# BlueNRG_LPF register map
File version: 1.0
CPU: CM0+ r0p0, little endian, no MPU, no FPU, 2 interrupt priority bits
Registers are 32-bit, read-write, reset 0x0 unless marked. A register's access mark holds for its fields unless they carry their own. Offsets are from the block's base; [hi:lo] are bit positions; {n}, {i} and the like mark numbered series.

## PWR
Base 0x48500000
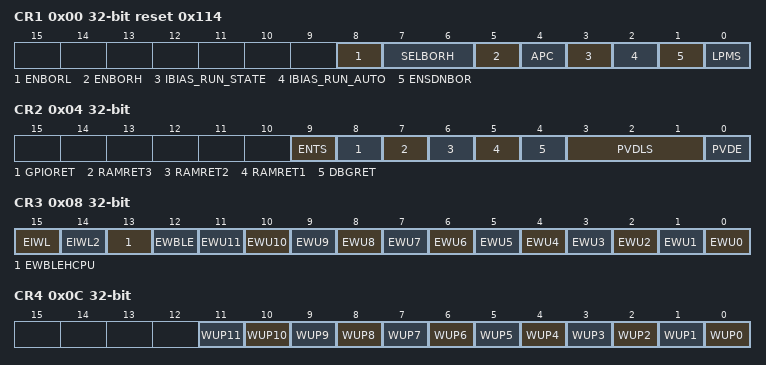
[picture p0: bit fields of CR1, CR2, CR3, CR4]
0x00 CR1 reset 0x114
  [8] ENBORL, [7:6] SELBORH, [5] ENBORH, [4] APC, [3] IBIAS_RUN_STATE, [2] IBIAS_RUN_AUTO, [1] ENSDNBOR, [0] LPMS
0x04 CR2
  [9] ENTS, [8] GPIORET, [7] RAMRET3, [6] RAMRET2, [5] RAMRET1, [4] DBGRET, [3:1] PVDLS, [0] PVDE
0x08 CR3
  [15] EIWL, [14] EIWL2, [13] EWBLEHCPU, [12] EWBLE, [n] EWU{n} (n=0..11)
0x0C CR4
  [n] WUP{n} (n=0..11)
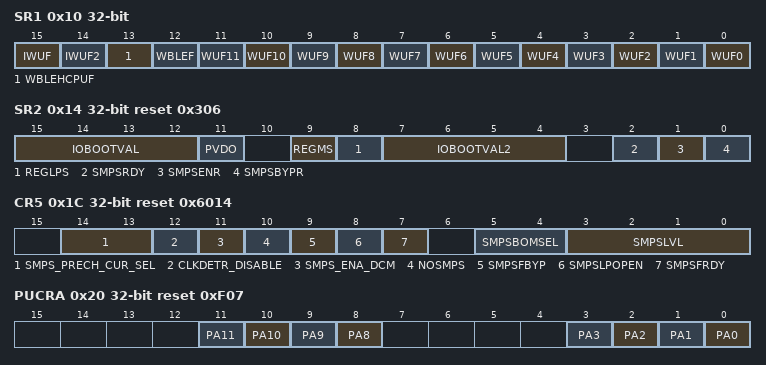
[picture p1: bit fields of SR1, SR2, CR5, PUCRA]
0x10 SR1
  [15] IWUF, [14] IWUF2, [13] WBLEHCPUF, [12] WBLEF, [n] WUF{n} (n=0..11)
0x14 SR2 ro reset 0x306
  [15:12] IOBOOTVAL, [11] PVDO, [9] REGMS, [8] REGLPS, [7:4] IOBOOTVAL2, [2] SMPSRDY, [1] SMPSENR, [0] SMPSBYPR
0x1C CR5 reset 0x6014
  [14:13] SMPS_PRECH_CUR_SEL, [12] CLKDETR_DISABLE, [11] SMPS_ENA_DCM, [10] NOSMPS, [9] SMPSFBYP, [8] SMPSLPOPEN, [7] SMPSFRDY, [5:4] SMPSBOMSEL, [3:0] SMPSLVL
0x20 PUCRA reset 0xF07
  [n] PA{n} (n=8..11), [n] PA{n} (n=0..3)
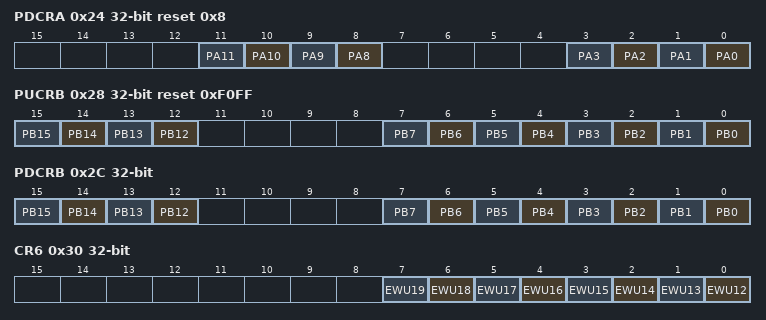
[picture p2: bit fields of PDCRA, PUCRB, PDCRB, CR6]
0x24 PDCRA reset 0x8
  [n] PA{n} (n=8..11), [n] PA{n} (n=0..3)
0x28 PUCRB reset 0xF0FF
  [n] PB{n} (n=12..15), [n] PB{n} (n=0..7)
0x2C PDCRB
  [n] PB{n} (n=12..15), [n] PB{n} (n=0..7)
0x30 CR6
  [n-12] EWU{n} (n=12..19)
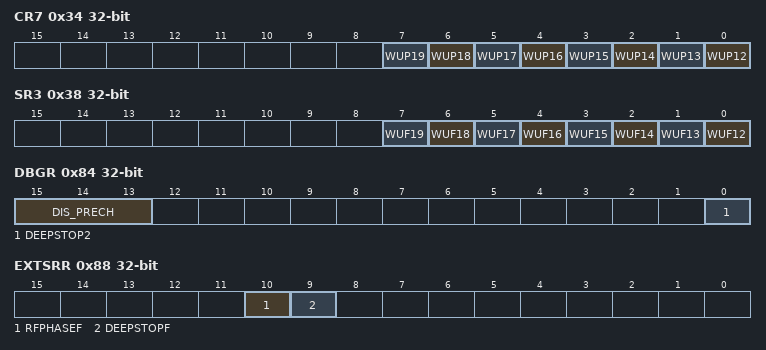
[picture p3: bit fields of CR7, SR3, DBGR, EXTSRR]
0x34 CR7
  [n-12] WUP{n} (n=12..19)
0x38 SR3
  [n-12] WUF{n} (n=12..19)
0x3C SDWN_WUEN
  [0] WUEN
0x40 SDWN_WUPOL
  [0] WUPOL
0x44 SDWN_WUF
  [0] WUF
0x84 DBGR
  [15:13] DIS_PRECH, [0] DEEPSTOP2
0x88 EXTSRR
  [10] RFPHASEF, [9] DEEPSTOPF
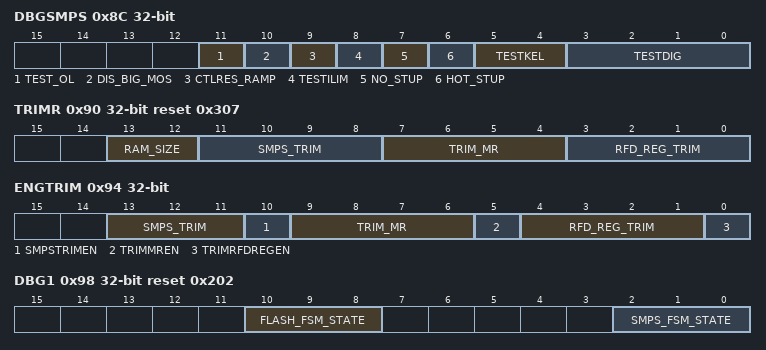
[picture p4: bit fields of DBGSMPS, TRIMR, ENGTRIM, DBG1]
0x8C DBGSMPS
  [11] TEST_OL, [10] DIS_BIG_MOS, [9] CTLRES_RAMP, [8] TESTILIM, [7] NO_STUP, [6] HOT_STUP, [5:4] TESTKEL, [3:0] TESTDIG
0x90 TRIMR ro reset 0x307
  [13:12] RAM_SIZE, [11:8] SMPS_TRIM, [7:4] TRIM_MR, [3:0] RFD_REG_TRIM
0x94 ENGTRIM
  [13:11] SMPS_TRIM, [10] SMPSTRIMEN, [9:6] TRIM_MR, [5] TRIMMREN, [4:1] RFD_REG_TRIM, [0] TRIMRFDREGEN
0x98 DBG1 ro reset 0x202
  [10:8] FLASH_FSM_STATE, [2:0] SMPS_FSM_STATE
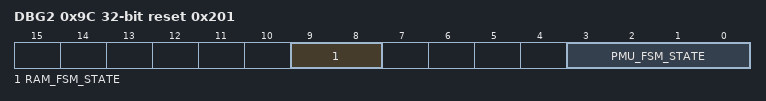
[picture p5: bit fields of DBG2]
0x9C DBG2 ro reset 0x201
  [9:8] RAM_FSM_STATE, [3:0] PMU_FSM_STATE

## RADIO_CTRL
Base 0x60001000
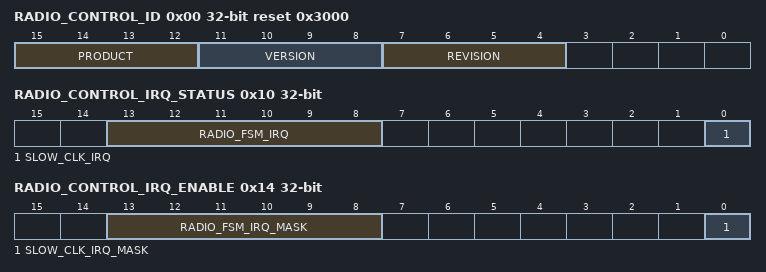
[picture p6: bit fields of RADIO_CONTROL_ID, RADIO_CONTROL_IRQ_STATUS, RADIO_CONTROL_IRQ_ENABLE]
0x00 RADIO_CONTROL_ID ro reset 0x3000 — identification register
  [15:12] PRODUCT, [11:8] VERSION, [7:4] REVISION
0x04 CLK32COUNT_REG reset 0x17 — window length register
  [8:0] SLOW_COUNT
0x08 CLK32PERIOD_REG ro — slow clock period
  [18:0] SLOW_PERIOD
0x0C CLK32FREQUENCY_REG ro — slow frequency register
  [26:0] SLOW_FREQUENCY
0x10 RADIO_CONTROL_IRQ_STATUS — interrupt status register
  [13:8] RADIO_FSM_IRQ, [0] SLOW_CLK_IRQ
0x14 RADIO_CONTROL_IRQ_ENABLE — interrupt enable register
  [13:8] RADIO_FSM_IRQ_MASK, [0] SLOW_CLK_IRQ_MASK

## RNG
Base 0x48600000
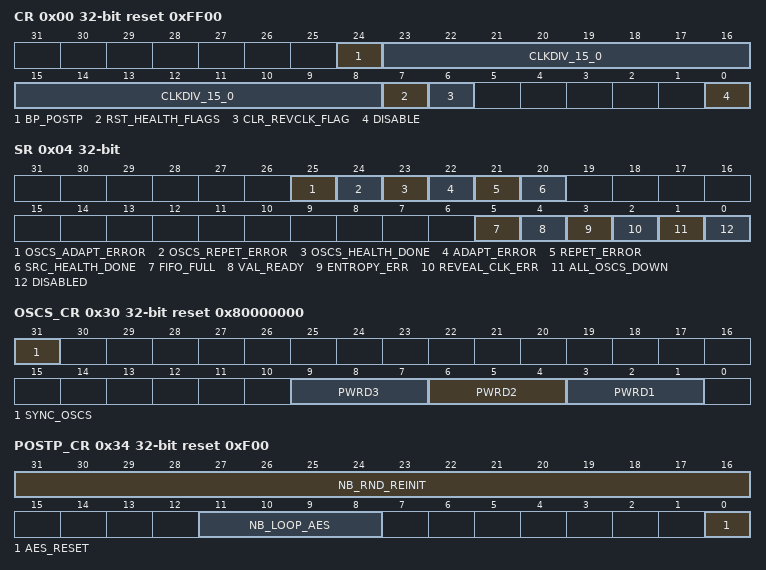
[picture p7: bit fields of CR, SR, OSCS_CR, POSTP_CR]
0x00 CR reset 0xFF00 — RNG_CR register
  [24] BP_POSTP, [23:8] CLKDIV_15_0, [7] RST_HEALTH_FLAGS, [6] CLR_REVCLK_FLAG, [0] DISABLE
0x04 SR ro — RNG_SR register
  [25] OSCS_ADAPT_ERROR, [24] OSCS_REPET_ERROR, [23] OSCS_HEALTH_DONE, [22] ADAPT_ERROR, [21] REPET_ERROR, [20] SRC_HEALTH_DONE, [5] FIFO_FULL, [4] VAL_READY, [3] ENTROPY_ERR, [2] REVEAL_CLK_ERR, [1] ALL_OSCS_DOWN, [0] DISABLED
0x08 VAL ro — RNG_VAL register
  [31:0] RND_VAL
0x30 OSCS_CR reset 0x80000000 — RNG_OSCS_CR register
  [31] SYNC_OSCS, [9:7] PWRD3, [6:4] PWRD2, [3:1] PWRD1
0x34 POSTP_CR reset 0xF00 — RNG_POSTP_CR register
  [31:16] NB_RND_REINIT, [11:8] NB_LOOP_AES, [0] AES_RESET
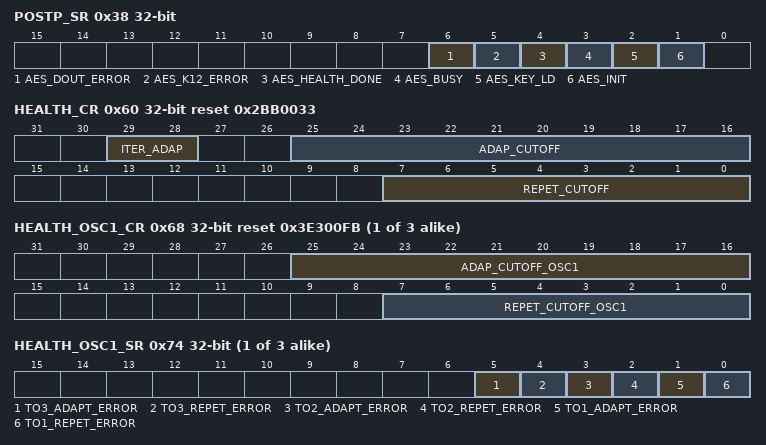
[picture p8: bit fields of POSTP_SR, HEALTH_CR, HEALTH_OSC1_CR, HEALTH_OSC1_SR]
0x38 POSTP_SR ro — RNG_POSTP_SR register
  [6] AES_DOUT_ERROR, [5] AES_K12_ERROR, [4] AES_HEALTH_DONE, [3] AES_BUSY, [2] AES_KEY_LD, [1] AES_INIT
{0x40+4i} DEFKEY{i} reset 0xFFFFFFFF (i=0..3) — RNG_DEFKEY{i} register
  [31:0] RNG_DEFKEY{i}
0x60 HEALTH_CR reset 0x2BB0033 — RNG_HEALTH_CR register
  [29:28] ITER_ADAP, [25:16] ADAP_CUTOFF, [7:0] REPET_CUTOFF
{0x64+4i} HEALTH_OSC{i}_CR reset 0x3E300FB (i=1..3) — RNG_HEALTH_OSC{i}_CR register
  [25:16] ADAP_CUTOFF_OSC{i}, [7:0] REPET_CUTOFF_OSC{i}
{0x70+4i} HEALTH_OSC{i}_SR ro (i=1..3) — RNG_HEALTH_OSC{i}_SR register
  [5] TO3_ADAPT_ERROR, [4] TO3_REPET_ERROR, [3] TO2_ADAPT_ERROR, [2] TO2_REPET_ERROR, [1] TO1_ADAPT_ERROR, [0] TO1_REPET_ERROR
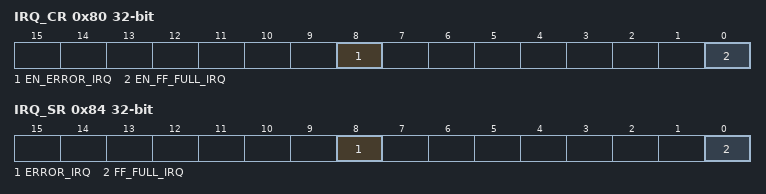
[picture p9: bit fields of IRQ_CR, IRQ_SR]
0x80 IRQ_CR — RNG_IRQ_CR register
  [8] EN_ERROR_IRQ, [0] EN_FF_FULL_IRQ
0x84 IRQ_SR ro — RNG_IRQ_SR register
  [8] ERROR_IRQ, [0] FF_FULL_IRQ
